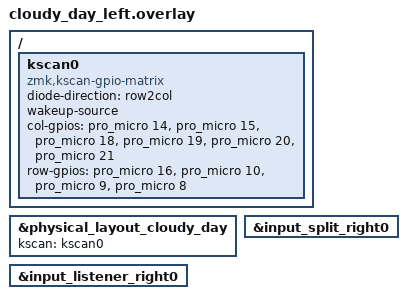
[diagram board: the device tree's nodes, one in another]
#include "cloudy_day.dtsi"

/ {
    kscan0: kscan0 {
        compatible = "zmk,kscan-gpio-matrix";
        diode-direction = "row2col";
        wakeup-source;

        col-gpios
            = <&pro_micro 14 (GPIO_ACTIVE_HIGH | GPIO_PULL_DOWN)>
            , <&pro_micro 15 (GPIO_ACTIVE_HIGH | GPIO_PULL_DOWN)>
            , <&pro_micro 18 (GPIO_ACTIVE_HIGH | GPIO_PULL_DOWN)>
            , <&pro_micro 19 (GPIO_ACTIVE_HIGH | GPIO_PULL_DOWN)>
            , <&pro_micro 20 (GPIO_ACTIVE_HIGH | GPIO_PULL_DOWN)>
            , <&pro_micro 21 (GPIO_ACTIVE_HIGH | GPIO_PULL_DOWN)>
            ;

        row-gpios
            = <&pro_micro 16 GPIO_ACTIVE_HIGH>
            , <&pro_micro 10 GPIO_ACTIVE_HIGH>
            , <&pro_micro 9 GPIO_ACTIVE_HIGH>
            , <&pro_micro 8 GPIO_ACTIVE_HIGH>
            ;
    };
};

&physical_layout_cloudy_day {
    kscan = <&kscan0>;
};
// == Input devices ==
// Input devices on peripheral parts
// Enabling input listeners and input-split to receive input events from peripherals
&input_split_right0 { status = "okay"; };
&input_listener_right0 { status = "okay"; };

